# cslr_adtf2 register map
Vendor: Texas Instruments
Peripheral module from a debugger description file (folder TCI6484_C6457).
Registers are 32-bit, access not given, reset 0x0 unless marked. A register's access mark holds for its fields unless they carry their own. Offsets are as the file gives them; lines under a group give offsets from that group; [hi:lo] are bit positions; {n}, {i} and the like mark numbered series; 'fields as' and 'values as' point back to an identical list; <NAME> marks a mode.

## ADTF2 — TI DSP to ATB Trace Wrapper
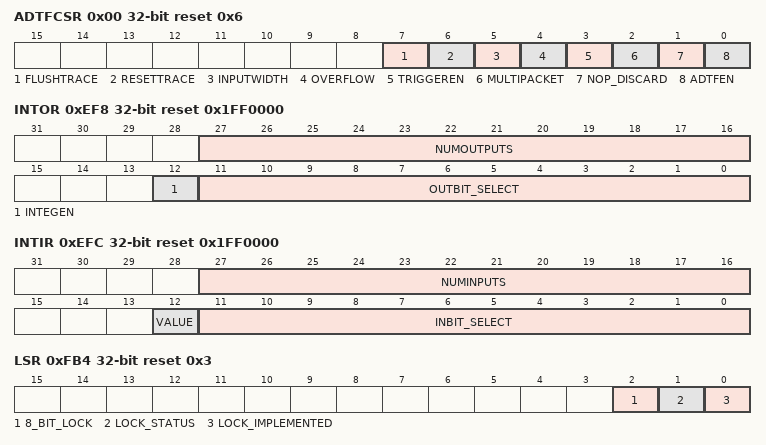
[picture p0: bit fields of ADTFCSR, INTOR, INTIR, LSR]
0x00 ADTFCSR reset 0x6 — Control and Status Register
  [7] FLUSHTRACE rw — Trace Flush.
    1=FLUSH_TRACE
  [6] RESETTRACE rw — Reset the DSP Trace input interface to the ADTF.
    1=RESET
  [5] INPUTWIDTH ro — Input port width determined at synthesis
    1=PORT_WIDTH_20; 0=PORT_WIDTH_10
  [4] OVERFLOW rw — Sticky status that the capture FIFO(s) have dropped at least one packet since last cleared.
    1=CLEAR
  [3] TRIGGEREN rw — Trigger Enable Disable Register.
    1=TRIGGER; 0=NO_TRIGGER
  [2] MULTIPACKET rw — Multiple packets or a single packet to be given to ETB.
    1=3_TRACE_PACKETS; 0=1_TRACE_PACKET
  [1] NOP_DISCARD rw — Discarding NOP packets.
    1=REMOVE_NOPS; 0=DONT_REMOVE_NOPS
  [0] ADTFEN rw — Enable/Disable ADFT2.
    1=ADFT2_FUNCTIONAL; 0=DISABLED
0x400 ADTFTID reset 0x60 — Trace ID Register
  [6:0] ATID rw — The ATID to output with valid trace data on the ATP interface.
0xEF8 INTOR reset 0x1FF0000 — Integration Output Register
  [27:16] NUMOUTPUTS ro — This field shall indicate the highest index of output terminals on the component
  [12] INTEGEN rw — When IntegEn=1, the integration outputs shall be enabled
    1=ENABLE; 0=DISABLE
  [11:0] OUTBIT_SELECT rw — This field shall selects the output bit to set high.
0xEFC INTIR reset 0x1FF0000 — Integration Input Register
  [27:16] NUMINPUTS ro — This field shall indicate the highest index of input terminals on the component
  [12] VALUE ro — This bit shall return the value of the selected input terminal
  [11:0] INBIT_SELECT rw — This field shall selects the input bit to read.
0xF00 INTCR — Integration Mode Control Register
  [0] ITM rw — When ITM=1, the ADTF2 shall be put into Integration Test Mode.
    1=ENABLE; 0=DISABLE
0xFA0 CTSR reset 0x1 — Claim Tag Set Register
  [0] CLAIM_TAG_SET rw — Writing a 1 shall sets the Claim Tag Value bit.
    1=SETCTV
0xFA4 CTCR — Claim Tag Clear Register
  [0] CLAIM_TAG_CLEAR rw — Writing a 1 shall clear the Claim Tag Value bit.
    1=CLEARCTV
0xFB0 LAR wo — Lock Access Register
  [31:0] WRITE_ACCESS_CODE — Writing 0xC5ACCE55 will unlock module for application access
    0xC5ACCE55=ENABLE
0xFB4 LSR reset 0x3 — Lock Status Register
  [2] 8_BIT_LOCK ro — 8bit or 32 bit LAR
    1=8_BIT; 0=32_BIT
  [1] LOCK_STATUS ro
    1=LOCKED; 0=UNLOCKED
  [0] LOCK_IMPLEMENTED ro — Is locking mechanism present
    0=NO_LOCK; 1=LOCK_MECH
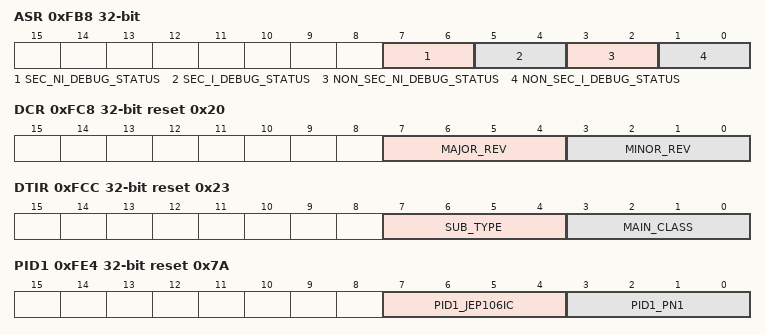
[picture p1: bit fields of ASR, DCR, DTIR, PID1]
0xFB8 ASR — Authentication Status Register
  [7:6] SEC_NI_DEBUG_STATUS ro — The Secure Non-Invasive Debug Status shall return 00.
  [5:4] SEC_I_DEBUG_STATUS ro — The Secure Invasive Debug Status shall return 00.
  [3:2] NON_SEC_NI_DEBUG_STATUS ro — The Non-Secure Non-Invasive Debug Status shall return 00.
  [1:0] NON_SEC_I_DEBUG_STATUS ro — The Non-Secure Invasive Debug Status shall return 00.
0xFC8 DCR reset 0x20 — Device Configuration Register
  [7:4] MAJOR_REV ro — Major revision of the ADTF
  [3:0] MINOR_REV ro — Minor revision of the ADTF
0xFCC DTIR reset 0x23 — Device Type Identifier Register
  [7:4] SUB_TYPE ro — Indicates source is DSP
  [3:0] MAIN_CLASS ro — Indicates the module is a trace source
0xFD0 PID4 — Peripheral ID4
  [3:0] PID4_JEP106CC ro — JEP106 Continuation Code
0xFE0 PID0 reset 0xDF — Peripheral ID0
  [7:0] PID0 ro — Part Number 0 (Middle and Lower BCD value of Device Number)
0xFE4 PID1 reset 0x7A — Peripheral ID1
  [7:4] PID1_JEP106IC ro — JEP106 identity code [3:0]
  [3:0] PID1_PN1 ro — Part Number 1 (Upper BCD value of Device Number)
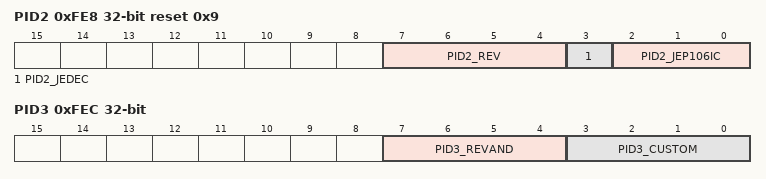
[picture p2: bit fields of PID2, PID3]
0xFE8 PID2 reset 0x9 — Peripheral ID2
  [7:4] PID2_REV ro — Revision  Revision Number of Peripheral.
  [3] PID2_JEDEC ro — Indicates that a JEDEC assigned value is used
  [2:0] PID2_JEP106IC ro — JEP106 identity code [6:4]
0xFEC PID3 — Peripheral ID3
  [7:4] PID3_REVAND ro — RevAnd (at top level)
  [3:0] PID3_CUSTOM ro — Customer Modified
0xFF0 CID0 reset 0xD — Component ID0
  [7:0] CID0 ro — This register shall return Preamble value 0x0D
0xFF4 CID1 reset 0x90 — Component ID1
  [7:0] CID1 ro — This register shall return Preamble value 0x90
0xFF8 CID2 reset 0x5 — Component ID2
  [7:0] CID2 ro — This register shall return Preamble value 0x05
0xFFC CID3 reset 0xB1 — Component ID3
  [7:0] CID3 ro — This register shall return Preamble value 0xB1
